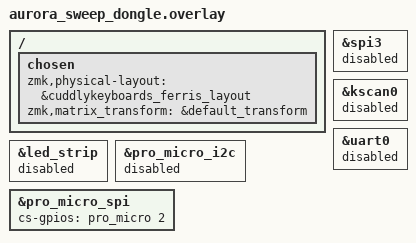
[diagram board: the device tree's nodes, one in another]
#include <dt-bindings/zmk/matrix_transform.h>

/* Import the base sweep layout */
#include "splitkb_aurora_sweep.dtsi"

/ {
    chosen {
        /* Point directly to the physical layout defined in the .dtsi */
        zmk,physical-layout = &cuddlykeyboards_ferris_layout;
        
        /* We completely omit zmk,kscan so it expects NO local keys */

        /* This so the Central can decode the right half's column offset */
        zmk,matrix_transform = &default_transform;
    };
};

/* 1. Kill the RGB LED driver hijacking MOSI (D16) */
&spi3 {
    status = "disabled";
};
&led_strip {
    status = "disabled";
};

/* 2. Kill the I2C OLED driver hijacking our CS pin (D2) */
&pro_micro_i2c {
    status = "disabled";
};

/* 3. Kill the Matrix scanner hijacking SCK (D15) */
&kscan0 {
    status = "disabled";
};

/* 4. Disable the hardware UART (Just to be safe) */
&uart0 {
    status = "disabled";
};

/* 5. Enable the SPI bus for the nice!view */
nice_view_spi: &pro_micro_spi {
    status = "okay";
    cs-gpios = <&pro_micro 2 GPIO_ACTIVE_HIGH>;
};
